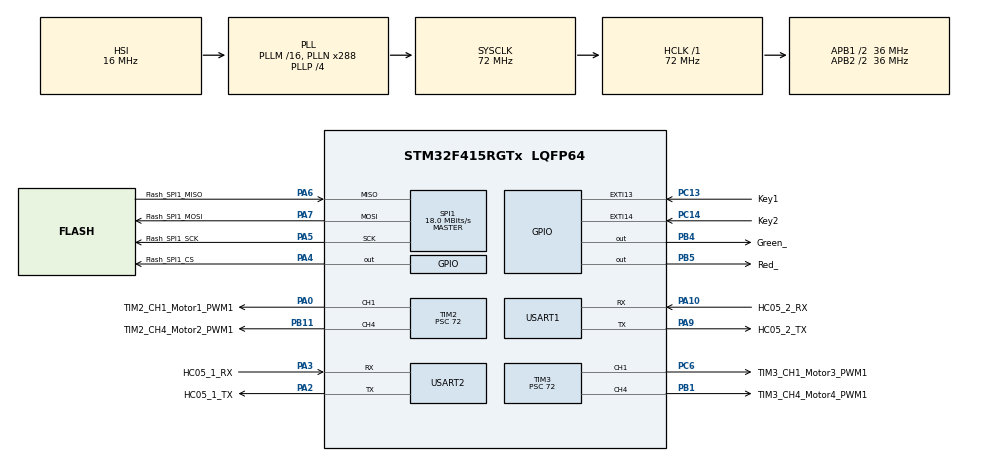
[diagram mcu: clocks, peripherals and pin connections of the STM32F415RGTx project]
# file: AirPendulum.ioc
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Dma.Request0=USART2_RX
Dma.Request1=USART2_TX
Dma.Request2=USART1_RX
Dma.Request3=USART1_TX
Dma.USART1_RX.2.Channel=DMA_CHANNEL_4
Dma.USART1_RX.2.Direction=DMA_PERIPH_TO_MEMORY
Dma.USART1_RX.2.FIFOMode=DMA_FIFOMODE_DISABLE
Dma.USART1_RX.2.Instance=DMA2_Stream2
Dma.USART1_RX.2.MemDataAlignment=DMA_MDATAALIGN_BYTE
Dma.USART1_RX.2.MemInc=DMA_MINC_ENABLE
Dma.USART1_RX.2.Mode=DMA_NORMAL
Dma.USART1_RX.2.PeriphDataAlignment=DMA_PDATAALIGN_BYTE
Dma.USART1_RX.2.PeriphInc=DMA_PINC_DISABLE
Dma.USART1_RX.2.Priority=DMA_PRIORITY_LOW
Dma.USART1_TX.3.Channel=DMA_CHANNEL_4
Dma.USART1_TX.3.Direction=DMA_MEMORY_TO_PERIPH
Dma.USART1_TX.3.FIFOMode=DMA_FIFOMODE_DISABLE
Dma.USART1_TX.3.Instance=DMA2_Stream7
Dma.USART1_TX.3.MemDataAlignment=DMA_MDATAALIGN_BYTE
Dma.USART1_TX.3.MemInc=DMA_MINC_DISABLE
Dma.USART1_TX.3.Mode=DMA_NORMAL
Dma.USART1_TX.3.PeriphDataAlignment=DMA_PDATAALIGN_BYTE
Dma.USART1_TX.3.PeriphInc=DMA_PINC_DISABLE
Dma.USART1_TX.3.Priority=DMA_PRIORITY_LOW
Dma.USART2_RX.0.Channel=DMA_CHANNEL_4
Dma.USART2_RX.0.Direction=DMA_PERIPH_TO_MEMORY
Dma.USART2_RX.0.FIFOMode=DMA_FIFOMODE_DISABLE
Dma.USART2_RX.0.Instance=DMA1_Stream5
Dma.USART2_RX.0.MemDataAlignment=DMA_MDATAALIGN_BYTE
Dma.USART2_RX.0.MemInc=DMA_MINC_ENABLE
Dma.USART2_RX.0.Mode=DMA_NORMAL
Dma.USART2_RX.0.PeriphDataAlignment=DMA_PDATAALIGN_BYTE
Dma.USART2_RX.0.PeriphInc=DMA_PINC_DISABLE
Dma.USART2_RX.0.Priority=DMA_PRIORITY_LOW
Dma.USART2_TX.1.Channel=DMA_CHANNEL_4
Dma.USART2_TX.1.Direction=DMA_MEMORY_TO_PERIPH
Dma.USART2_TX.1.FIFOMode=DMA_FIFOMODE_DISABLE
Dma.USART2_TX.1.Instance=DMA1_Stream6
Dma.USART2_TX.1.MemDataAlignment=DMA_MDATAALIGN_BYTE
Dma.USART2_TX.1.MemInc=DMA_MINC_DISABLE
Dma.USART2_TX.1.Mode=DMA_NORMAL
Dma.USART2_TX.1.PeriphDataAlignment=DMA_PDATAALIGN_BYTE
Dma.USART2_TX.1.PeriphInc=DMA_PINC_DISABLE
Dma.USART2_TX.1.Priority=DMA_PRIORITY_LOW
Mcu.Family=STM32F4
Mcu.Name=STM32F415RGTx
Mcu.Package=LQFP64
NVIC.DMA1_Stream5_IRQn=true\:2\:0\:true
NVIC.DMA1_Stream6_IRQn=true\:2\:0\:true
NVIC.DMA2_Stream2_IRQn=true\:3\:0\:true
NVIC.DMA2_Stream7_IRQn=true\:3\:0\:true
NVIC.PriorityGroup=NVIC_PRIORITYGROUP_4
NVIC.SPI1_IRQn=true\:0\:0\:false
NVIC.TIM1_TRG_COM_TIM11_IRQn=true\:0\:0\:false
NVIC.TIM7_IRQn=true\:0\:0\:false
NVIC.USART1_IRQn=true\:1\:0\:true
NVIC.USART2_IRQn=true\:0\:0\:false
PA0-WKUP.GPIO_Label=TIM2_CH1_Motor1_PWM1
PA0-WKUP.GPIO_ModeDefaultPP=GPIO_MODE_AF_PP
PA0-WKUP.GPIO_PuPd=GPIO_NOPULL
PA0-WKUP.GPIO_Speed=GPIO_SPEED_LOW
PA0-WKUP.Signal=S_TIM2_CH1_ETR
PA1.GPIO_Label=Motor1_PWM2
PA1.GPIO_ModeDefaultPP=GPIO_MODE_AF_PP
PA1.GPIO_PuPd=GPIO_NOPULL
PA1.GPIO_Speed=GPIO_SPEED_LOW
PA1.Signal=S_TIM2_CH2
PA10.GPIO_Label=HC05_2_RX
PA10.GPIO_Mode=GPIO_MODE_AF_PP
PA10.GPIO_PuPd=GPIO_PULLUP
PA10.GPIO_Speed=GPIO_SPEED_HIGH
PA10.Mode=Asynchronous
PA10.Signal=USART1_RX
PA13.Mode=Serial-Wire
PA13.Signal=SYS_JTMS-SWDIO
PA14.Mode=Serial-Wire
PA14.Signal=SYS_JTCK-SWCLK
PA2.GPIO_Label=HC05_1_TX
PA2.GPIO_Mode=GPIO_MODE_AF_PP
PA2.GPIO_PuPd=GPIO_PULLUP
PA2.GPIO_Speed=GPIO_SPEED_HIGH
PA2.Mode=Asynchronous
PA2.Signal=USART2_TX
PA3.GPIO_Label=HC05_1_RX
PA3.GPIO_Mode=GPIO_MODE_AF_PP
PA3.GPIO_PuPd=GPIO_PULLUP
PA3.GPIO_Speed=GPIO_SPEED_HIGH
PA3.Mode=Asynchronous
PA3.Signal=USART2_RX
PA4.GPIO_Label=Flash_SPI1_CS
PA4.GPIO_ModeDefaultOutputPP=GPIO_MODE_OUTPUT_PP
PA4.GPIO_PuPd=GPIO_NOPULL
PA4.GPIO_Speed=GPIO_SPEED_LOW
PA4.Signal=GPIO_Output
PA5.GPIO_Label=Flash_SPI1_SCK
PA5.GPIO_Mode=GPIO_MODE_AF_PP
PA5.GPIO_PuPd=GPIO_NOPULL
PA5.GPIO_Speed=GPIO_SPEED_HIGH
PA5.Mode=Full_Duplex_Master
PA5.Signal=SPI1_SCK
PA6.GPIO_Label=Flash_SPI1_MISO
PA6.GPIO_Mode=GPIO_MODE_AF_PP
PA6.GPIO_PuPd=GPIO_NOPULL
PA6.GPIO_Speed=GPIO_SPEED_HIGH
PA6.Mode=Full_Duplex_Master
PA6.Signal=SPI1_MISO
PA7.GPIO_Label=Flash_SPI1_MOSI
PA7.GPIO_Mode=GPIO_MODE_AF_PP
PA7.GPIO_PuPd=GPIO_NOPULL
PA7.GPIO_Speed=GPIO_SPEED_HIGH
PA7.Mode=Full_Duplex_Master
PA7.Signal=SPI1_MOSI
PA9.GPIO_Label=HC05_2_TX
PA9.GPIO_Mode=GPIO_MODE_AF_PP
PA9.GPIO_PuPd=GPIO_PULLUP
PA9.GPIO_Speed=GPIO_SPEED_HIGH
PA9.Mode=Asynchronous
PA9.Signal=USART1_TX
PB0.GPIO_Label=Motor4_PWM2
PB0.GPIO_ModeDefaultPP=GPIO_MODE_AF_PP
PB0.GPIO_PuPd=GPIO_NOPULL
PB0.GPIO_Speed=GPIO_SPEED_LOW
PB0.Signal=S_TIM3_CH3
PB1.GPIO_Label=TIM3_CH4_Motor4_PWM1
PB1.GPIO_ModeDefaultPP=GPIO_MODE_AF_PP
PB1.GPIO_PuPd=GPIO_NOPULL
PB1.GPIO_Speed=GPIO_SPEED_LOW
PB1.Signal=S_TIM3_CH4
PB10.GPIO_Label=Motor2_PWM2
PB10.GPIO_ModeDefaultPP=GPIO_MODE_AF_PP
PB10.GPIO_PuPd=GPIO_NOPULL
PB10.GPIO_Speed=GPIO_SPEED_LOW
PB10.Signal=S_TIM2_CH3
PB11.GPIO_Label=TIM2_CH4_Motor2_PWM1
PB11.GPIO_ModeDefaultPP=GPIO_MODE_AF_PP
PB11.GPIO_PuPd=GPIO_NOPULL
PB11.GPIO_Speed=GPIO_SPEED_LOW
PB11.Signal=S_TIM2_CH4
PB4.GPIO_Label=Green_
PB4.GPIO_ModeDefaultOutputPP=GPIO_MODE_OUTPUT_PP
PB4.GPIO_PuPd=GPIO_NOPULL
PB4.GPIO_Speed=GPIO_SPEED_LOW
PB4.Signal=GPIO_Output
PB5.GPIO_Label=Red_
PB5.GPIO_ModeDefaultOutputPP=GPIO_MODE_OUTPUT_PP
PB5.GPIO_PuPd=GPIO_NOPULL
PB5.GPIO_Speed=GPIO_SPEED_LOW
PB5.Signal=GPIO_Output
PC13-ANTI_TAMP.GPIO_Label=Key1
PC13-ANTI_TAMP.GPIO_ModeDefaultEXTI=GPIO_MODE_EVT_RISING
PC13-ANTI_TAMP.GPIO_PuPd=GPIO_NOPULL
PC13-ANTI_TAMP.Signal=GPXTI13
PC14-OSC32_IN.GPIO_Label=Key2
PC14-OSC32_IN.GPIO_ModeDefaultEXTI=GPIO_MODE_EVT_RISING
PC14-OSC32_IN.GPIO_PuPd=GPIO_NOPULL
PC14-OSC32_IN.Signal=GPXTI14
PC6.GPIO_Label=TIM3_CH1_Motor3_PWM1
PC6.GPIO_ModeDefaultPP=GPIO_MODE_AF_PP
PC6.GPIO_PuPd=GPIO_NOPULL
PC6.GPIO_Speed=GPIO_SPEED_LOW
PC6.Signal=S_TIM3_CH1
PC7.GPIO_Label=Motor3_PW2
PC7.GPIO_ModeDefaultPP=GPIO_MODE_AF_PP
PC7.GPIO_PuPd=GPIO_NOPULL
PC7.GPIO_Speed=GPIO_SPEED_LOW
PC7.Signal=S_TIM3_CH2
ProjectManager.TargetToolchain=MDK-ARM V4
RCC.48MHZClocksFreq_Value=72000000
RCC.AHBFreq_Value=72000000
RCC.APB1CLKDivider=RCC_HCLK_DIV2
RCC.APB1Freq_Value=36000000
RCC.APB1TimFreq_Value=72000000
RCC.APB2CLKDivider=RCC_HCLK_DIV2
RCC.APB2Freq_Value=36000000
RCC.APB2TimFreq_Value=72000000
RCC.CortexFreq_Value=9000000
RCC.Cortex_Div=SYSTICK_CLKSOURCE_HCLK_DIV8
RCC.HCLKFreq_Value=72000000
RCC.HSE_VALUE=25000000
RCC.HSI_VALUE=16000000
RCC.LSE_VALUE=32768
RCC.PLLN=288
RCC.PLLP=RCC_PLLP_DIV4
RCC.SYSCLKFreq_VALUE=72000000
RCC.SYSCLKSource=RCC_SYSCLKSOURCE_PLLCLK
RCC.VCOOutputFreq_Value=288000000
SH.S_TIM2_CH1_ETR.0=TIM2_CH1,PWM Generation1 CH1
SH.S_TIM2_CH2.0=TIM2_CH2
SH.S_TIM2_CH3.0=TIM2_CH3
SH.S_TIM2_CH4.0=TIM2_CH4,PWM Generation4 CH4
SH.S_TIM3_CH1.0=TIM3_CH1,PWM Generation1 CH1
SH.S_TIM3_CH2.0=TIM3_CH2
SH.S_TIM3_CH3.0=TIM3_CH3
SH.S_TIM3_CH4.0=TIM3_CH4,PWM Generation4 CH4
SPI1.BaudRatePrescaler=SPI_BAUDRATEPRESCALER_2
SPI1.CalculateBaudRate=18.0 MBits/s
SPI1.Mode=SPI_MODE_MASTER
TIM10.Period=65535
TIM10.Prescaler=36000
TIM11.Period=2000
TIM11.Prescaler=36000
TIM13.Period=65535
TIM13.Prescaler=72
TIM14.Period=65535
TIM14.Prescaler=72
TIM2.Channel-PWM\ Generation4\ CH4=TIM_CHANNEL_4
TIM2.Period=2000
TIM2.Prescaler=72
TIM2.Pulse-PWM\ Generation1\ CH1=2000
TIM2.Pulse-PWM\ Generation4\ CH4=2000
TIM3.Channel-PWM\ Generation4\ CH4=TIM_CHANNEL_4
TIM3.Period=2000
TIM3.Prescaler=72
TIM3.Pulse-PWM\ Generation1\ CH1=2000
TIM3.Pulse-PWM\ Generation4\ CH4=2000
TIM7.Period=2000
TIM7.Prescaler=72
VP_TIM10_VS_ClockSourceINT.Mode=Enable_Timer
VP_TIM11_VS_ClockSourceINT.Mode=Enable_Timer
VP_TIM13_VS_ClockSourceINT.Mode=Enable_Timer
VP_TIM14_VS_ClockSourceINT.Mode=Enable_Timer
VP_TIM2_VS_ClockSourceINT.Mode=Internal
VP_TIM3_VS_ClockSourceINT.Mode=Internal
VP_TIM7_VS_ClockSourceINT.Mode=Enable_Timer
board=custom

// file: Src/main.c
/**
  ******************************************************************************
  * File Name          : main.c
  * Description        : Main program body
  ******************************************************************************
  *
  * COPYRIGHT(c) 2015 STMicroelectronics
  *
  * Redistribution and use in source and binary forms, with or without modification,
  * are permitted provided that the following conditions are met:
  *   1. Redistributions of source code must retain the above copyright notice,
  *      this list of conditions and the following disclaimer.
  *   2. Redistributions in binary form must reproduce the above copyright notice,
  *      this list of conditions and the following disclaimer in the documentation
  *      and/or other materials provided with the distribution.
  *   3. Neither the name of STMicroelectronics nor the names of its contributors
  *      may be used to endorse or promote products derived from this software
  *      without specific prior written permission.
  *
  * THIS SOFTWARE IS PROVIDED BY THE COPYRIGHT HOLDERS AND CONTRIBUTORS "AS IS"
  * AND ANY EXPRESS OR IMPLIED WARRANTIES, INCLUDING, BUT NOT LIMITED TO, THE
  * IMPLIED WARRANTIES OF MERCHANTABILITY AND FITNESS FOR A PARTICULAR PURPOSE ARE
  * DISCLAIMED. IN NO EVENT SHALL THE COPYRIGHT HOLDER OR CONTRIBUTORS BE LIABLE
  * FOR ANY DIRECT, INDIRECT, INCIDENTAL, SPECIAL, EXEMPLARY, OR CONSEQUENTIAL
  * DAMAGES (INCLUDING, BUT NOT LIMITED TO, PROCUREMENT OF SUBSTITUTE GOODS OR
  * SERVICES; LOSS OF USE, DATA, OR PROFITS; OR BUSINESS INTERRUPTION) HOWEVER
  * CAUSED AND ON ANY THEORY OF LIABILITY, WHETHER IN CONTRACT, STRICT LIABILITY,
  * OR TORT (INCLUDING NEGLIGENCE OR OTHERWISE) ARISING IN ANY WAY OUT OF THE USE
  * OF THIS SOFTWARE, EVEN IF ADVISED OF THE POSSIBILITY OF SUCH DAMAGE.
  *
  ******************************************************************************
  */

#include "stm32f4xx_hal.h"
#include "dma.h"
#include "spi.h"
#include "tim.h"
#include "usart.h"
#include "gpio.h"

void SystemClock_Config(void);

int main(void)
{

  /* MCU Configuration----------------------------------------------------------*/

  /* Reset of all peripherals, Initializes the Flash interface and the Systick. */
  HAL_Init();

  /* Configure the system clock */
  SystemClock_Config();

  /* Initialize all configured peripherals */
  MX_GPIO_Init();
  MX_DMA_Init();
  MX_SPI1_Init();
  MX_TIM2_Init();
  MX_TIM3_Init();
  MX_TIM7_Init();
  MX_TIM10_Init();
  MX_TIM11_Init();
  MX_TIM13_Init();
  MX_TIM14_Init();
  MX_USART1_UART_Init();
  MX_USART2_UART_Init();

  /* USER CODE BEGIN 2 */

	HAL_TIM_PWM_Start(&htim2, TIM_CHANNEL_1);      //Motor1
	HAL_TIM_PWM_Start(&htim2, TIM_CHANNEL_4);      //Motor2
	HAL_TIM_PWM_Start(&htim3, TIM_CHANNEL_1);      //Motor3
	HAL_TIM_PWM_Start(&htim3, TIM_CHANNEL_4);      //Motor4

  /* USER CODE END 2 */

  /* Infinite loop */
  while (1)
  {

  }

}

/** System Clock Configuration
*/
void SystemClock_Config(void)
{

  RCC_OscInitTypeDef RCC_OscInitStruct;
  RCC_ClkInitTypeDef RCC_ClkInitStruct;

  __PWR_CLK_ENABLE();

  __HAL_PWR_VOLTAGESCALING_CONFIG(PWR_REGULATOR_VOLTAGE_SCALE2);

  RCC_OscInitStruct.OscillatorType = RCC_OSCILLATORTYPE_HSI;
  RCC_OscInitStruct.HSIState = RCC_HSI_ON;
  RCC_OscInitStruct.HSICalibrationValue = 16;
  RCC_OscInitStruct.PLL.PLLState = RCC_PLL_ON;
  RCC_OscInitStruct.PLL.PLLSource = RCC_PLLSOURCE_HSI;
  RCC_OscInitStruct.PLL.PLLM = 16;
  RCC_OscInitStruct.PLL.PLLN = 288;
  RCC_OscInitStruct.PLL.PLLP = RCC_PLLP_DIV4;
  RCC_OscInitStruct.PLL.PLLQ = 4;
  HAL_RCC_OscConfig(&RCC_OscInitStruct);

  RCC_ClkInitStruct.ClockType = RCC_CLOCKTYPE_SYSCLK|RCC_CLOCKTYPE_PCLK1
                              |RCC_CLOCKTYPE_PCLK2;
  RCC_ClkInitStruct.SYSCLKSource = RCC_SYSCLKSOURCE_PLLCLK;
  RCC_ClkInitStruct.AHBCLKDivider = RCC_SYSCLK_DIV1;
  RCC_ClkInitStruct.APB1CLKDivider = RCC_HCLK_DIV2;
  RCC_ClkInitStruct.APB2CLKDivider = RCC_HCLK_DIV2;
  HAL_RCC_ClockConfig(&RCC_ClkInitStruct, FLASH_LATENCY_2);

  HAL_SYSTICK_Config(HAL_RCC_GetHCLKFreq()/8000);

  HAL_SYSTICK_CLKSourceConfig(SYSTICK_CLKSOURCE_HCLK_DIV8);

}

/************************ (C) COPYRIGHT STMicroelectronics *****END OF FILE****/
